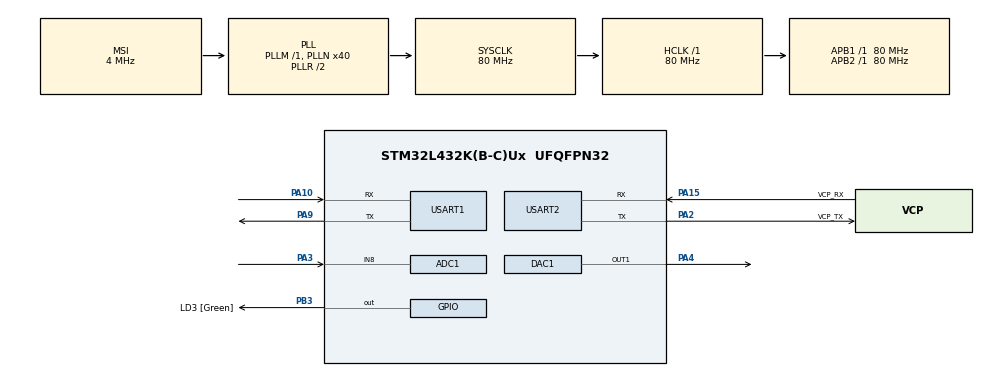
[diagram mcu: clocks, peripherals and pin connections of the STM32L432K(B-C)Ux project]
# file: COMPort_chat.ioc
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ADC1.Channel-0\#ChannelRegularConversion=ADC_CHANNEL_8
ADC1.NbrOfConversionFlag=1
ADC1.OffsetNumber-0\#ChannelRegularConversion=ADC_OFFSET_NONE
ADC1.Rank-0\#ChannelRegularConversion=1
ADC1.SamplingTime-0\#ChannelRegularConversion=ADC_SAMPLETIME_2CYCLES_5
ADC1.master=1
Mcu.Family=STM32L4
Mcu.Name=STM32L432K(B-C)Ux
Mcu.Package=UFQFPN32
NVIC.PriorityGroup=NVIC_PRIORITYGROUP_4
NVIC.USART1_IRQn=true\:0\:0\:false\:false\:true\:true\:true
PA0.GPIO_Label=MCO [High speed clock in]
PA0.Mode=HSE-External-Clock-Source-for-LittleOrca
PA0.Signal=RCC_CK_IN
PA10.Mode=Asynchronous
PA10.Signal=USART1_RX
PA13\ (JTMS-SWDIO).GPIO_Label=SWDIO
PA13\ (JTMS-SWDIO).Mode=Serial_Wire
PA13\ (JTMS-SWDIO).Signal=SYS_JTMS-SWDIO
PA14\ (JTCK-SWCLK).GPIO_Label=SWCLK
PA14\ (JTCK-SWCLK).Mode=Serial_Wire
PA14\ (JTCK-SWCLK).Signal=SYS_JTCK-SWCLK
PA15\ (JTDI).GPIO_Label=VCP_RX
PA15\ (JTDI).Mode=Asynchronous
PA15\ (JTDI).Signal=USART2_RX
PA2.GPIO_Label=VCP_TX
PA2.Mode=Asynchronous
PA2.Signal=USART2_TX
PA3.Signal=ADCx_IN8
PA4.Signal=COMP_DAC11_group
PA9.Mode=Asynchronous
PA9.Signal=USART1_TX
PB3\ (JTDO-TRACESWO).GPIO_Label=LD3 [Green]
PB3\ (JTDO-TRACESWO).Signal=GPIO_Output
PC14-OSC32_IN\ (PC14).Mode=LSE-External-Oscillator
PC14-OSC32_IN\ (PC14).Signal=RCC_OSC32_IN
PC15-OSC32_OUT\ (PC15).Mode=LSE-External-Oscillator
PC15-OSC32_OUT\ (PC15).Signal=RCC_OSC32_OUT
ProjectManager.HeapSize=0x200
ProjectManager.StackSize=0x400
ProjectManager.TargetToolchain=TrueSTUDIO
RCC.ADCFreq_Value=40000000
RCC.AHBFreq_Value=80000000
RCC.APB1Freq_Value=80000000
RCC.APB1TimFreq_Value=80000000
RCC.APB2Freq_Value=80000000
RCC.APB2TimFreq_Value=80000000
RCC.CortexFreq_Value=80000000
RCC.HCLKFreq_Value=80000000
RCC.HSI16_VALUE=16000000
RCC.HSI48_VALUE=48000000
RCC.HSI_VALUE=16000000
RCC.MSI_VALUE=4000000
RCC.PLLMUL=RCC_PLLMUL_4
RCC.PLLN=40
RCC.PLLSAI1N=20
RCC.SYSCLKFreq_VALUE=80000000
RCC.SYSCLKSource=RCC_SYSCLKSOURCE_PLLCLK
RCC.USBFreq_Value=40000000
RCC.VCOOutputFreq_Value=160000000
SH.ADCx_IN8.0=ADC1_IN8,IN8-Single-Ended
SH.COMP_DAC11_group.0=DAC1_OUT1,DAC_OUT1
USART1.VirtualMode-Asynchronous=VM_ASYNC
USART2.VirtualMode-Asynchronous=VM_ASYNC
board=NUCLEO-L432KC

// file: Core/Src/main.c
/* USER CODE BEGIN Header */
/**
  ******************************************************************************
  * @file           : main.c
  * @brief          : Main program body
  ******************************************************************************
  * @attention
  *
  * <h2><center>&copy; Copyright (c) 2021 STMicroelectronics.
  * All rights reserved.</center></h2>
  *
  * This software component is licensed by ST under BSD 3-Clause license,
  * the "License"; You may not use this file except in compliance with the
  * License. You may obtain a copy of the License at:
  *                        opensource.org/licenses/BSD-3-Clause
  *
  ******************************************************************************
  */
/* USER CODE END Header */
#include "main.h"

/* USER CODE BEGIN Includes */
#include <stdio.h>
#include <string.h>
/* USER CODE END Includes */

ADC_HandleTypeDef hadc1;

DAC_HandleTypeDef hdac1;

UART_HandleTypeDef huart1;
UART_HandleTypeDef huart2;

/* USER CODE BEGIN PV */
__IO ITStatus UartReady = SET;
char Buff[255] = "Whatever\r\n";
char Buffin[255] = "Whatever\r\n";
uint8_t c_str, len_str;
/* USER CODE END PV */

void SystemClock_Config(void);
static void MX_GPIO_Init(void);
static void MX_ADC1_Init(void);
static void MX_DAC1_Init(void);
static void MX_USART1_UART_Init(void);
static void MX_USART2_UART_Init(void);
/* USER CODE BEGIN PFP */

uint8_t uart_receive(int8_t *addrB);

/* USER CODE END PFP */

int main(void)
{

  /* MCU Configuration--------------------------------------------------------*/

  /* Reset of all peripherals, Initializes the Flash interface and the Systick. */
  HAL_Init();

  /* Configure the system clock */
  SystemClock_Config();

  /* Initialize all configured peripherals */
  MX_GPIO_Init();
  MX_ADC1_Init();
  MX_DAC1_Init();
  MX_USART1_UART_Init();
  MX_USART2_UART_Init();
  /* USER CODE BEGIN 2 */
  HAL_NVIC_SetPriority(USART2_IRQn, 0, 0);
  HAL_NVIC_EnableIRQ(USART2_IRQn);

  HAL_Delay(200);
  c_str = sprintf(Buff, "System Clock: %lu kHz\r\nSYSCLK: %lu kHz\r\n", SystemCoreClock/1000, HAL_RCC_GetSysClockFreq()/1000);
  HAL_UART_Transmit(&huart1, (uint8_t *) Buff, c_str, 200);

  /* USER CODE END 2 */

  /* Infinite loop */
  while (1)
  {
	    len_str = c_str = 0; Buff[0] = '\0';
//	    HAL_UART_Receive(&huart1, (uint8_t *) Buffin, 80, 200);
	    len_str = uart_receive(Buffin);
	    if(strlen(Buffin) > 0) {
	    	HAL_UART_Transmit(&huart2, (uint8_t *) Buffin, (uint16_t) strlen(Buffin), 200);
	    	for (c_str = 0; c_str < 255; c_str++) Buffin[c_str] = '\0';
	    }
	    if(len_str > 0) {
	    	sprintf(Buff, "Bytes: %d", len_str);
	    	HAL_UART_Transmit(&huart1, (uint8_t *) Buff, strlen(Buff), 200);
	    	for (c_str = 0; c_str < 255; c_str++) Buff[c_str] = '\0';
	    }
//	    HAL_UART_AbortReceive(&huart1);

	    HAL_GPIO_TogglePin(GPIOB, LD3_Pin);
  }
}

/*
 * Function to write on the buffer whatever comes from UART in interrupt mode
 */
uint8_t uart_receive(int8_t *addrB){
	int8_t retVal = 0;
	while(UartReady == SET){
		HAL_UART_Receive_IT(&huart1, (uint8_t *) (addrB + retVal), 1);
		if(addrB[retVal] == '\n') UartReady = RESET;
		retVal++;
	}
	addrB[retVal] = '\0';
	return retVal;
}

void HAL_UART_RxCpltCallback(UART_HandleTypeDef *UartHandle) {
 /* Set transmission flag: transfer complete*/
 UartReady = SET;
}

void SystemClock_Config(void)
{
  RCC_OscInitTypeDef RCC_OscInitStruct = {0};
  RCC_ClkInitTypeDef RCC_ClkInitStruct = {0};
  RCC_PeriphCLKInitTypeDef PeriphClkInit = {0};

  /** Configure LSE Drive Capability
  */
  HAL_PWR_EnableBkUpAccess();
  __HAL_RCC_LSEDRIVE_CONFIG(RCC_LSEDRIVE_LOW);
  /** Initializes the RCC Oscillators according to the specified parameters
  * in the RCC_OscInitTypeDef structure.
  */
  RCC_OscInitStruct.OscillatorType = RCC_OSCILLATORTYPE_LSE|RCC_OSCILLATORTYPE_MSI;
  RCC_OscInitStruct.LSEState = RCC_LSE_ON;
  RCC_OscInitStruct.MSIState = RCC_MSI_ON;
  RCC_OscInitStruct.MSICalibrationValue = 0;
  RCC_OscInitStruct.MSIClockRange = RCC_MSIRANGE_6;
  RCC_OscInitStruct.PLL.PLLState = RCC_PLL_ON;
  RCC_OscInitStruct.PLL.PLLSource = RCC_PLLSOURCE_MSI;
  RCC_OscInitStruct.PLL.PLLM = 1;
  RCC_OscInitStruct.PLL.PLLN = 40;
  RCC_OscInitStruct.PLL.PLLP = RCC_PLLP_DIV7;
  RCC_OscInitStruct.PLL.PLLQ = RCC_PLLQ_DIV2;
  RCC_OscInitStruct.PLL.PLLR = RCC_PLLR_DIV2;
  if (HAL_RCC_OscConfig(&RCC_OscInitStruct) != HAL_OK)
  {
    Error_Handler();
  }
  /** Initializes the CPU, AHB and APB buses clocks
  */
  RCC_ClkInitStruct.ClockType = RCC_CLOCKTYPE_HCLK|RCC_CLOCKTYPE_SYSCLK
                              |RCC_CLOCKTYPE_PCLK1|RCC_CLOCKTYPE_PCLK2;
  RCC_ClkInitStruct.SYSCLKSource = RCC_SYSCLKSOURCE_PLLCLK;
  RCC_ClkInitStruct.AHBCLKDivider = RCC_SYSCLK_DIV1;
  RCC_ClkInitStruct.APB1CLKDivider = RCC_HCLK_DIV1;
  RCC_ClkInitStruct.APB2CLKDivider = RCC_HCLK_DIV1;

  if (HAL_RCC_ClockConfig(&RCC_ClkInitStruct, FLASH_LATENCY_4) != HAL_OK)
  {
    Error_Handler();
  }
  PeriphClkInit.PeriphClockSelection = RCC_PERIPHCLK_USART1|RCC_PERIPHCLK_USART2
                              |RCC_PERIPHCLK_ADC;
  PeriphClkInit.Usart1ClockSelection = RCC_USART1CLKSOURCE_PCLK2;
  PeriphClkInit.Usart2ClockSelection = RCC_USART2CLKSOURCE_PCLK1;
  PeriphClkInit.AdcClockSelection = RCC_ADCCLKSOURCE_PLLSAI1;
  PeriphClkInit.PLLSAI1.PLLSAI1Source = RCC_PLLSOURCE_MSI;
  PeriphClkInit.PLLSAI1.PLLSAI1M = 1;
  PeriphClkInit.PLLSAI1.PLLSAI1N = 20;
  PeriphClkInit.PLLSAI1.PLLSAI1P = RCC_PLLP_DIV7;
  PeriphClkInit.PLLSAI1.PLLSAI1Q = RCC_PLLQ_DIV2;
  PeriphClkInit.PLLSAI1.PLLSAI1R = RCC_PLLR_DIV2;
  PeriphClkInit.PLLSAI1.PLLSAI1ClockOut = RCC_PLLSAI1_ADC1CLK;
  if (HAL_RCCEx_PeriphCLKConfig(&PeriphClkInit) != HAL_OK)
  {
    Error_Handler();
  }
  /** Configure the main internal regulator output voltage
  */
  if (HAL_PWREx_ControlVoltageScaling(PWR_REGULATOR_VOLTAGE_SCALE1) != HAL_OK)
  {
    Error_Handler();
  }
  /** Enable MSI Auto calibration
  */
  HAL_RCCEx_EnableMSIPLLMode();
}

static void MX_ADC1_Init(void)
{

  ADC_ChannelConfTypeDef sConfig = {0};

  /** Common config
  */
  hadc1.Instance = ADC1;
  hadc1.Init.ClockPrescaler = ADC_CLOCK_ASYNC_DIV1;
  hadc1.Init.Resolution = ADC_RESOLUTION_12B;
  hadc1.Init.DataAlign = ADC_DATAALIGN_RIGHT;
  hadc1.Init.ScanConvMode = ADC_SCAN_DISABLE;
  hadc1.Init.EOCSelection = ADC_EOC_SINGLE_CONV;
  hadc1.Init.LowPowerAutoWait = DISABLE;
  hadc1.Init.ContinuousConvMode = DISABLE;
  hadc1.Init.NbrOfConversion = 1;
  hadc1.Init.DiscontinuousConvMode = DISABLE;
  hadc1.Init.ExternalTrigConv = ADC_SOFTWARE_START;
  hadc1.Init.ExternalTrigConvEdge = ADC_EXTERNALTRIGCONVEDGE_NONE;
  hadc1.Init.DMAContinuousRequests = DISABLE;
  hadc1.Init.Overrun = ADC_OVR_DATA_PRESERVED;
  hadc1.Init.OversamplingMode = DISABLE;
  if (HAL_ADC_Init(&hadc1) != HAL_OK)
  {
    Error_Handler();
  }
  /** Configure Regular Channel
  */
  sConfig.Channel = ADC_CHANNEL_8;
  sConfig.Rank = ADC_REGULAR_RANK_1;
  sConfig.SamplingTime = ADC_SAMPLETIME_2CYCLES_5;
  sConfig.SingleDiff = ADC_SINGLE_ENDED;
  sConfig.OffsetNumber = ADC_OFFSET_NONE;
  sConfig.Offset = 0;
  if (HAL_ADC_ConfigChannel(&hadc1, &sConfig) != HAL_OK)
  {
    Error_Handler();
  }

}

static void MX_DAC1_Init(void)
{

  DAC_ChannelConfTypeDef sConfig = {0};

  /** DAC Initialization
  */
  hdac1.Instance = DAC1;
  if (HAL_DAC_Init(&hdac1) != HAL_OK)
  {
    Error_Handler();
  }
  /** DAC channel OUT1 config
  */
  sConfig.DAC_SampleAndHold = DAC_SAMPLEANDHOLD_DISABLE;
  sConfig.DAC_Trigger = DAC_TRIGGER_NONE;
  sConfig.DAC_OutputBuffer = DAC_OUTPUTBUFFER_ENABLE;
  sConfig.DAC_ConnectOnChipPeripheral = DAC_CHIPCONNECT_DISABLE;
  sConfig.DAC_UserTrimming = DAC_TRIMMING_FACTORY;
  if (HAL_DAC_ConfigChannel(&hdac1, &sConfig, DAC_CHANNEL_1) != HAL_OK)
  {
    Error_Handler();
  }

}

static void MX_USART1_UART_Init(void)
{

  huart1.Instance = USART1;
  huart1.Init.BaudRate = 115200;
  huart1.Init.WordLength = UART_WORDLENGTH_8B;
  huart1.Init.StopBits = UART_STOPBITS_1;
  huart1.Init.Parity = UART_PARITY_NONE;
  huart1.Init.Mode = UART_MODE_TX_RX;
  huart1.Init.HwFlowCtl = UART_HWCONTROL_NONE;
  huart1.Init.OverSampling = UART_OVERSAMPLING_16;
  huart1.Init.OneBitSampling = UART_ONE_BIT_SAMPLE_DISABLE;
  huart1.AdvancedInit.AdvFeatureInit = UART_ADVFEATURE_NO_INIT;
  if (HAL_UART_Init(&huart1) != HAL_OK)
  {
    Error_Handler();
  }

}

static void MX_USART2_UART_Init(void)
{

  huart2.Instance = USART2;
  huart2.Init.BaudRate = 115200;
  huart2.Init.WordLength = UART_WORDLENGTH_8B;
  huart2.Init.StopBits = UART_STOPBITS_1;
  huart2.Init.Parity = UART_PARITY_NONE;
  huart2.Init.Mode = UART_MODE_TX_RX;
  huart2.Init.HwFlowCtl = UART_HWCONTROL_NONE;
  huart2.Init.OverSampling = UART_OVERSAMPLING_16;
  huart2.Init.OneBitSampling = UART_ONE_BIT_SAMPLE_DISABLE;
  huart2.AdvancedInit.AdvFeatureInit = UART_ADVFEATURE_NO_INIT;
  if (HAL_UART_Init(&huart2) != HAL_OK)
  {
    Error_Handler();
  }

}

static void MX_GPIO_Init(void)
{
  GPIO_InitTypeDef GPIO_InitStruct = {0};

  /* GPIO Ports Clock Enable */
  __HAL_RCC_GPIOC_CLK_ENABLE();
  __HAL_RCC_GPIOA_CLK_ENABLE();
  __HAL_RCC_GPIOB_CLK_ENABLE();

  /*Configure GPIO pin Output Level */
  HAL_GPIO_WritePin(LD3_GPIO_Port, LD3_Pin, GPIO_PIN_RESET);

  /*Configure GPIO pin : LD3_Pin */
  GPIO_InitStruct.Pin = LD3_Pin;
  GPIO_InitStruct.Mode = GPIO_MODE_OUTPUT_PP;
  GPIO_InitStruct.Pull = GPIO_NOPULL;
  GPIO_InitStruct.Speed = GPIO_SPEED_FREQ_LOW;
  HAL_GPIO_Init(LD3_GPIO_Port, &GPIO_InitStruct);

}

void Error_Handler(void)
{
}

/************************ (C) COPYRIGHT STMicroelectronics *****END OF FILE****/
